# MPU_INTC register map
Vendor: Texas Instruments
Peripheral module from a debugger description file (folder omap34xx).
Registers are 32-bit, access per field, reset 0x0 unless marked. A register's access mark holds for its fields unless they carry their own. Offsets are as the file gives them; lines under a group give offsets from that group; [hi:lo] are bit positions; {n}, {i} and the like mark numbered series; 'fields as' and 'values as' point back to an identical list; <NAME> marks a mode.

## MPU_INTC
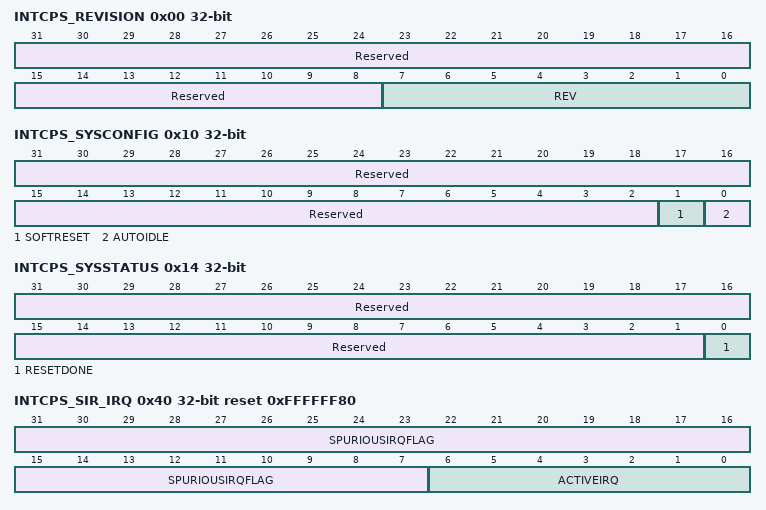
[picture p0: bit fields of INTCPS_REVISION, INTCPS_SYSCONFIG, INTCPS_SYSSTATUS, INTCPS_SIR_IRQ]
0x00 INTCPS_REVISION ro (reset mask 0xFFFFFF00) — This register contains the IP revision code.
  [31:8] Reserved — Read returns reset value.
  [7:0] REV — IP revision[7:4] Major revision[3:0] Minor revisionExamples: 0x10 for 1.0, 0x21 for 2.1
0x10 INTCPS_SYSCONFIG — This register controls various parameters of the module interface.
  [31:2] Reserved ro — Write 0s for future compatibility. Read returns reset value.
  [1] SOFTRESET rw — Software reset. Set this bit to trigger a module reset. The bit is automatically reset by the hardware. Read returns 0.
    0=SOFTRESET_0_w (No functional effect); 1=SOFTRESET_1_w (The module is reset.)
  [0] AUTOIDLE rw — Internal interface clock gating strategy
    0=Interface clock is free-running; 1=Automatic interface clock gating strategy is applied, based on the interface bus activity
0x14 INTCPS_SYSSTATUS ro (reset mask 0xFFFFFFFE) — This register provides status information about the module.
  [31:1] Reserved — Read returns reset value.
  [0] RESETDONE — Internal reset monitoring
    0=RESETDONE_0_r (Internal module reset is ongoing.); 1=RESETDONE_1_r (Reset complete)
0x40 INTCPS_SIR_IRQ ro reset 0xFFFFFF80 — This register supplies the currently active IRQ interrupt number.
  [31:7] SPURIOUSIRQFLAG
  [6:0] ACTIVEIRQ — Active IRQ number
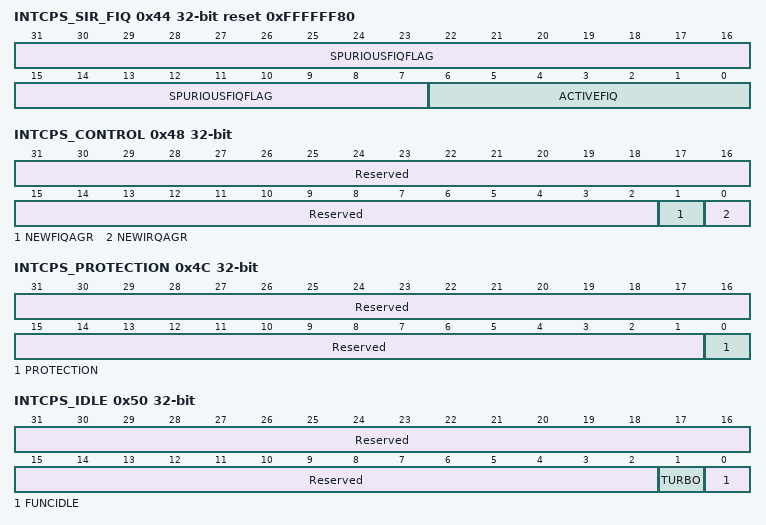
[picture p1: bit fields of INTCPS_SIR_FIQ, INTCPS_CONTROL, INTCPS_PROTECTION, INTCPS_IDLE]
0x44 INTCPS_SIR_FIQ ro reset 0xFFFFFF80 — This register supplies the currently active FIQ interrupt number.
  [31:7] SPURIOUSFIQFLAG
  [6:0] ACTIVEFIQ — Active FIQ number
0x48 INTCPS_CONTROL (reset mask 0xFFFFFFFC) — This register contains the new interrupt agreement bits.
  [31:2] Reserved ro — Write 0s for future compatibility. Read returns reset value.
  [1] NEWFIQAGR wo — Reset FIQ output and enable new FIQ generation.
    0=NEWFIQAGR_0_w (No functional effect); 1=NEWFIQAGR_1_w (Reset FIQ output and enable new FIQ generation.)
  [0] NEWIRQAGR wo — New IRQ generation
    0=NEWIRQAGR_0_w (No functional effect); 1=NEWIRQAGR_1_w (Reset IRQ output and enable new IRQ generation.)
0x4C INTCPS_PROTECTION — This register controls protection of the other registers. It can be accessed only in supervisor mode, regardless of the current value of the protection bit.
  [31:1] Reserved ro — Write 0s for future compatibility. Read returns reset value.
  [0] PROTECTION rw — Protection mode
    0=Protection mode is disabled (default); 1=Protection mode is enabled. When enabled, all the MPU INTC registers are accessible only in privileged mode.
0x50 INTCPS_IDLE — This register controls the functional clock auto-idle and the synchronizer clock auto-gating.
  [31:2] Reserved ro — Write 0s for future compatibility. Read returns reset value.
  [1] TURBO rw — Input synchronizer clock auto-gating
    0=Input synchronizer clock is free-running (default); 1=Input synchronizer clock is auto-gated based on interrupt input activity
  [0] FUNCIDLE rw — Functional clock idle mode
    0=Functional clock gating strategy is applied (default); 1=Functional clock is free-running
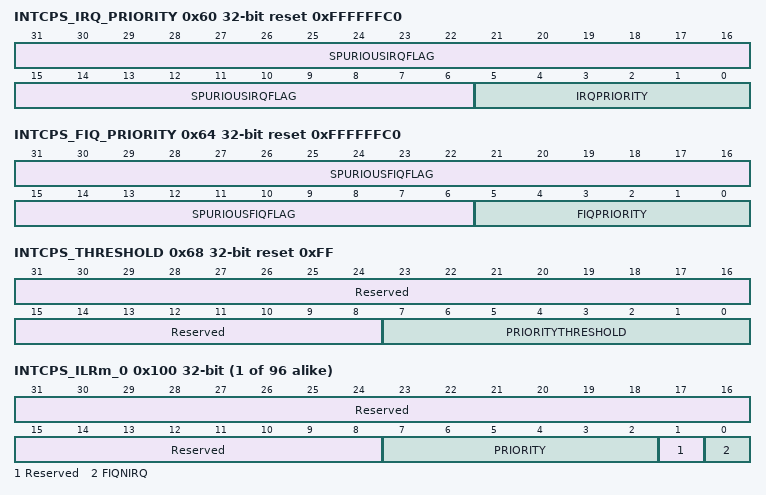
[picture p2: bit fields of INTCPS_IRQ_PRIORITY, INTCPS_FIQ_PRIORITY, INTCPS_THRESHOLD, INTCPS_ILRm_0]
0x60 INTCPS_IRQ_PRIORITY ro reset 0xFFFFFFC0 — This register supplies the currently active IRQ priority level.
  [31:6] SPURIOUSIRQFLAG
  [5:0] IRQPRIORITY — Current IRQ priority
0x64 INTCPS_FIQ_PRIORITY ro reset 0xFFFFFFC0 — This register supplies the currently active FIQ priority level.
  [31:6] SPURIOUSFIQFLAG
  [5:0] FIQPRIORITY — Current FIQ priority
0x68 INTCPS_THRESHOLD reset 0xFF — This register sets the priority threshold.
  [31:8] Reserved ro — Write 0s for future compatibility. Read returns reset value.
  [7:0] PRIORITYTHRESHOLD rw — Priority thresholdWrite 0x0 to 0x3F: Priority threshold enabled .
    255=PRIORITYTHRESHOLD_255_w (Priority threshold disabled)
{0x80+0x20*i} INTCPS_ITRn_{i} ro reset not defined (i=0..2) — This register shows the raw interrupt input status before masking.
  [31:0] ITR — Interrupt status before masking
{0x84+0x20*i} INTCPS_MIRn_{i} rw reset 0xFFFFFFFF (i=0..2) — This register contains the interrupt mask.
  [31:0] MIR — Interrupt mask
    1=The interrupt is masked; 0=The interrupt is unmasked
{0x88+0x20*i} INTCPS_MIR_CLEARn_{i} wo (i=0..2) — This register is used to clear the interrupt mask bits.
  [31:0] MIRCLEAR
    1=MIRCLEAR_1_w (Clears the MIR mask bit to 0); 0=MIRCLEAR_0_w (No functional effect)
{0x8C+0x20*i} INTCPS_MIR_SETn_{i} wo (i=0..2) — This register is used to set the interrupt mask bits.
  [31:0] MIRSET
    0=MIRSET_0_w (No functional effect); 1=MIRSET_1_w (Sets the MIR mask bit to 1.)
{0x90+0x20*i} INTCPS_ISR_SETn_{i} rw (i=0..2) — This register is used to set the software interrupt bits. It is also used to read the currently active software interrupts.
  [31:0] ISRSET — Set the software interrupt bits. Read returns the currently active software interrupts.
    0=ISRSET_0_w (No functional effect); 1=ISRSET_1_w (Sets the software interrupt bits to 1.)
{0x94+0x20*i} INTCPS_ISR_CLEARn_{i} wo (i=0..2) — This register is used to clear the software interrupt bits.
  [31:0] ISRCLEAR
    0=ISRCLEAR_0_w (No functional effect); 1=ISRCLEAR_1_w (Clears the software interrupt bits to 0.)
{0x98+0x20*i} INTCPS_PENDING_IRQn_{i} ro (i=0..2) — This register contains the IRQ status after masking.
  [31:0] PENDINGIRQ — IRQ status after masking.
{0x9C+0x20*i} INTCPS_PENDING_FIQn_{i} ro (i=0..2) — This register contains the FIQ status after masking.
  [31:0] PENDINGFIQ — FIQ status after masking.
{0x100+4i} INTCPS_ILRm_{i} (i=0..95) — These registers contain the priority for the interrupts and the FIQ/IRQ steering.
  [31:8] Reserved ro — Write 0s for future compatibility. Read returns reset value.
  [7:2] PRIORITY rw — Interrupt priority
  [1] Reserved ro — Write 0 for future compatibility. Read returns reset value.
  [0] FIQNIRQ rw — Interrupt IRQ FIQ mapping. Read returns reset value.
    0=FIQNIRQ_0_w (Interrupt is routed to IRQ.); 1=FIQNIRQ_1_w (Interrupt is routed to FIQ.)
